# LCD_A_1 register map
Vendor: Texas Instruments
Peripheral module from a debugger description file (folder msp430).
Registers are 8-bit, access not given, no defined reset value unless marked. A register's access mark holds for its fields unless they carry their own. Offsets are as the file gives them; lines under a group give offsets from that group; [hi:lo] are bit positions; {n}, {i} and the like mark numbered series; 'fields as' and 'values as' point back to an identical list; <NAME> marks a mode.

## LCD_A
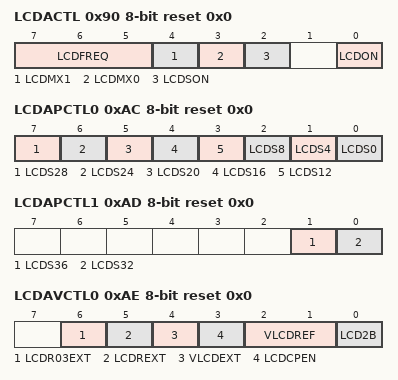
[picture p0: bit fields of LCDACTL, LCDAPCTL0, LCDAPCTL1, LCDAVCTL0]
0x90 LCDACTL rw reset 0x0 — LCD_A Control Register
  [7:5] LCDFREQ, [4] LCDMX1, [3] LCDMX0, [2] LCDSON, [0] LCDON
{0x90+i} LCDM{i} (i=1..20) — LCD Memory {i}
0xAC LCDAPCTL0 rw reset 0x0 — LCD_A Port Control Register 0
  [7] LCDS28 — LCD Segment 28 to 31 Enable.
  [6] LCDS24 — LCD Segment 24 to 27 Enable.
  [5] LCDS20 — LCD Segment 20 to 23 Enable.
  [4] LCDS16 — LCD Segment 16 to 19 Enable.
  [3] LCDS12 — LCD Segment 12 to 15 Enable.
  [2] LCDS8 — LCD Segment 8 to 11 Enable.
  [1] LCDS4 — LCD Segment 4 to 7 Enable.
  [0] LCDS0 — LCD Segment 0 to 3 Enable.
0xAD LCDAPCTL1 rw reset 0x0 — LCD_A Port Control Register 1
  [1] LCDS36 — LCD Segment 36 to 39 Enable.
  [0] LCDS32 — LCD Segment 32 to 35 Enable.
0xAE LCDAVCTL0 rw reset 0x0 — LCD_A Voltage Control Register 0
  [6] LCDR03EXT — Selects external connection for lowest LCD voltage.
  [5] LCDREXT — Selects external connections for LCD mid voltages.
  [4] VLCDEXT — Select external source for VLCD.
  [3] LCDCPEN — LCD Voltage Charge Pump Enable.
  [2:1] VLCDREF — Selects reference voltage for regulated charge pump: 0
    0=Internal; 1=External
  [0] LCD2B — Selects 1/2 bias.
0xAF LCDAVCTL1 rw reset 0x0 — LCD_A Voltage Control Register 1
  [4:1] VLCD — VLCD select: 0
    0=Charge pump disabled; 1=VLCD = 2.60V; 2=VLCD = 2.66V; 3=VLCD = 2.72V; 4=VLCD = 2.78V; 5=VLCD = 2.84V; 6=VLCD = 2.90V; 7=VLCD = 2.96V; 8=VLCD = 3.02V; 9=VLCD = 3.08V; 10=VLCD = 3.14V; 11=VLCD = 3.20V; 12=VLCD = 3.26V; 13=VLCD = 3.32V; 14=VLCD = 3.38V; 15=VLCD = 3.44V
